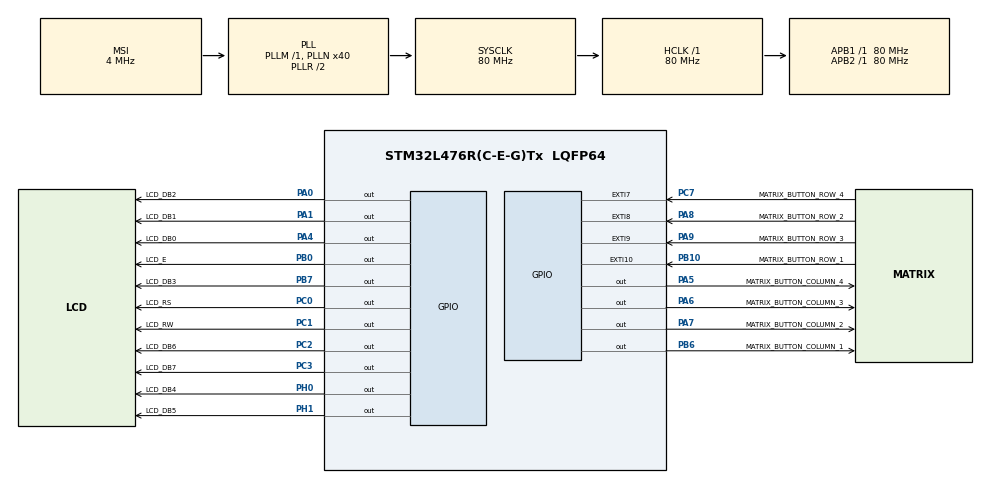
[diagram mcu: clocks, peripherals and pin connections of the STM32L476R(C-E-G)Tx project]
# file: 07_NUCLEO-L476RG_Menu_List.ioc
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Mcu.Family=STM32L4
Mcu.Name=STM32L476R(C-E-G)Tx
Mcu.Package=LQFP64
Mcu.UserConstants=TIMER_PRESCALER,7999;TIMER_COUNTER,9;LCD_TIMER_PRESCALER,1;LCD_TIMER_COUNTER,3
NVIC.EXTI15_10_IRQn=true\:1\:0\:true\:false\:true\:true\:true
NVIC.EXTI9_5_IRQn=true\:1\:0\:true\:false\:true\:true\:true
NVIC.PriorityGroup=NVIC_PRIORITYGROUP_4
NVIC.RTC_WKUP_IRQn=true\:0\:0\:false\:false\:true\:true\:true
NVIC.TIM6_DAC_IRQn=true\:1\:0\:true\:false\:true\:true\:true
NVIC.TIM7_IRQn=true\:0\:0\:true\:false\:true\:true\:true
PA0.GPIO_Label=LCD_DB2
PA0.GPIO_Speed=GPIO_SPEED_FREQ_VERY_HIGH
PA0.Signal=GPIO_Output
PA1.GPIO_Label=LCD_DB1
PA1.GPIO_Speed=GPIO_SPEED_FREQ_VERY_HIGH
PA1.Signal=GPIO_Output
PA4.GPIO_Label=LCD_DB0
PA4.GPIO_Speed=GPIO_SPEED_FREQ_VERY_HIGH
PA4.Signal=GPIO_Output
PA5.GPIO_Label=MATRIX_BUTTON_COLUMN_4
PA5.GPIO_ModeDefaultOutputPP=GPIO_MODE_OUTPUT_OD
PA5.Signal=GPIO_Output
PA6.GPIO_Label=MATRIX_BUTTON_COLUMN_3
PA6.GPIO_ModeDefaultOutputPP=GPIO_MODE_OUTPUT_OD
PA6.Signal=GPIO_Output
PA7.GPIO_Label=MATRIX_BUTTON_COLUMN_2
PA7.GPIO_ModeDefaultOutputPP=GPIO_MODE_OUTPUT_OD
PA7.Signal=GPIO_Output
PA8.GPIO_Label=MATRIX_BUTTON_ROW_2
PA8.GPIO_ModeDefaultEXTI=GPIO_MODE_IT_FALLING
PA8.GPIO_PuPd=GPIO_PULLUP
PA8.Signal=GPXTI8
PA9.GPIO_Label=MATRIX_BUTTON_ROW_3
PA9.GPIO_ModeDefaultEXTI=GPIO_MODE_IT_FALLING
PA9.GPIO_PuPd=GPIO_PULLUP
PA9.Signal=GPXTI9
PB0.GPIO_Label=LCD_E
PB0.GPIO_Speed=GPIO_SPEED_FREQ_VERY_HIGH
PB0.Signal=GPIO_Output
PB10.GPIO_Label=MATRIX_BUTTON_ROW_1
PB10.GPIO_ModeDefaultEXTI=GPIO_MODE_IT_FALLING
PB10.GPIO_PuPd=GPIO_PULLUP
PB10.Signal=GPXTI10
PB6.GPIO_Label=MATRIX_BUTTON_COLUMN_1
PB6.GPIO_ModeDefaultOutputPP=GPIO_MODE_OUTPUT_OD
PB6.Signal=GPIO_Output
PB7.GPIO_Label=LCD_DB3
PB7.GPIO_Speed=GPIO_SPEED_FREQ_VERY_HIGH
PB7.Signal=GPIO_Output
PC0.GPIO_Label=LCD_RS
PC0.GPIO_Speed=GPIO_SPEED_FREQ_VERY_HIGH
PC0.Signal=GPIO_Output
PC1.GPIO_Label=LCD_RW
PC1.GPIO_Speed=GPIO_SPEED_FREQ_VERY_HIGH
PC1.Signal=GPIO_Output
PC2.GPIO_Label=LCD_DB6
PC2.GPIO_Speed=GPIO_SPEED_FREQ_VERY_HIGH
PC2.Signal=GPIO_Output
PC3.GPIO_Label=LCD_DB7
PC3.GPIO_Speed=GPIO_SPEED_FREQ_VERY_HIGH
PC3.Signal=GPIO_Output
PC7.GPIO_Label=MATRIX_BUTTON_ROW_4
PC7.GPIO_ModeDefaultEXTI=GPIO_MODE_IT_FALLING
PC7.GPIO_PuPd=GPIO_PULLUP
PC7.Signal=GPXTI7
PH0-OSC_IN\ (PH0).GPIO_Label=LCD_DB4
PH0-OSC_IN\ (PH0).GPIO_Speed=GPIO_SPEED_FREQ_VERY_HIGH
PH0-OSC_IN\ (PH0).Signal=GPIO_Output
PH1-OSC_OUT\ (PH1).GPIO_Label=LCD_DB5
PH1-OSC_OUT\ (PH1).GPIO_Speed=GPIO_SPEED_FREQ_VERY_HIGH
PH1-OSC_OUT\ (PH1).Signal=GPIO_Output
ProjectManager.HeapSize=0x200
ProjectManager.StackSize=0x400
ProjectManager.TargetToolchain=STM32CubeIDE
RCC.AHBFreq_Value=80000000
RCC.APB1Freq_Value=80000000
RCC.APB1TimFreq_Value=80000000
RCC.APB2Freq_Value=80000000
RCC.APB2TimFreq_Value=80000000
RCC.CortexFreq_Value=80000000
RCC.HCLKFreq_Value=80000000
RCC.HSE_VALUE=8000000
RCC.HSI_VALUE=16000000
RCC.LSE_VALUE=32768
RCC.MSI_VALUE=4000000
RCC.PLLN=40
RCC.SYSCLKFreq_VALUE=80000000
RCC.SYSCLKSource=RCC_SYSCLKSOURCE_PLLCLK
RCC.VCOOutputFreq_Value=160000000
RTC.Date=26
RTC.Format=RTC_FORMAT_BIN
RTC.Hours=23
RTC.Minutes=30
RTC.Month=RTC_MONTH_MAY
RTC.Seconds=30
RTC.WakeUpClock-WakeUp=RTC_WAKEUPCLOCK_CK_SPRE_16BITS
RTC.WeekDay=RTC_WEEKDAY_TUESDAY
TIM6.Period=TIMER_COUNTER
TIM6.Prescaler=TIMER_PRESCALER
TIM7.Period=LCD_TIMER_COUNTER
TIM7.Prescaler=LCD_TIMER_PRESCALER
VP_RTC_VS_RTC_Activate.Mode=RTC_Enabled
VP_RTC_VS_RTC_Calendar.Mode=RTC_Calendar
VP_RTC_VS_RTC_WakeUp_intern.Mode=WakeUp
VP_TIM6_VS_ClockSourceINT.Mode=Enable_Timer
VP_TIM7_VS_ClockSourceINT.Mode=Enable_Timer
board=custom

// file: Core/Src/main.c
/* USER CODE BEGIN Header */
/**
  ******************************************************************************
  * @file           : main.c
  * @brief          : Main program body
  ******************************************************************************
  * @attention
  *
  * <h2><center>&copy; Copyright (c) 2020 STMicroelectronics.
  * All rights reserved.</center></h2>
  *
  * This software component is licensed by ST under BSD 3-Clause license,
  * the "License"; You may not use this file except in compliance with the
  * License. You may obtain a copy of the License at:
  *                        opensource.org/licenses/BSD-3-Clause
  *
  ******************************************************************************
  */
/* USER CODE END Header */

#include "main.h"
#include "rtc.h"
#include "tim.h"
#include "gpio.h"

/* USER CODE BEGIN Includes */
#include "common.h"
#include "main_loop.h"
/* USER CODE END Includes */

void SystemClock_Config(void);

int main(void)
{

  /* MCU Configuration--------------------------------------------------------*/

  /* Reset of all peripherals, Initializes the Flash interface and the Systick. */
  HAL_Init();

  /* Configure the system clock */
  SystemClock_Config();

  /* Initialize all configured peripherals */
  MX_GPIO_Init();
  MX_TIM6_Init();
  MX_TIM7_Init();
  MX_RTC_Init();

  /* Infinite loop */
  /* USER CODE BEGIN WHILE */
  while (1)
  {
	  MainLoop();
    /* USER CODE END WHILE */

  }
}

void SystemClock_Config(void)
{
  RCC_OscInitTypeDef RCC_OscInitStruct = {0};
  RCC_ClkInitTypeDef RCC_ClkInitStruct = {0};
  RCC_PeriphCLKInitTypeDef PeriphClkInit = {0};

  /** Initializes the CPU, AHB and APB busses clocks
  */
  RCC_OscInitStruct.OscillatorType = RCC_OSCILLATORTYPE_LSI|RCC_OSCILLATORTYPE_MSI;
  RCC_OscInitStruct.LSIState = RCC_LSI_ON;
  RCC_OscInitStruct.MSIState = RCC_MSI_ON;
  RCC_OscInitStruct.MSICalibrationValue = 0;
  RCC_OscInitStruct.MSIClockRange = RCC_MSIRANGE_6;
  RCC_OscInitStruct.PLL.PLLState = RCC_PLL_ON;
  RCC_OscInitStruct.PLL.PLLSource = RCC_PLLSOURCE_MSI;
  RCC_OscInitStruct.PLL.PLLM = 1;
  RCC_OscInitStruct.PLL.PLLN = 40;
  RCC_OscInitStruct.PLL.PLLP = RCC_PLLP_DIV7;
  RCC_OscInitStruct.PLL.PLLQ = RCC_PLLQ_DIV2;
  RCC_OscInitStruct.PLL.PLLR = RCC_PLLR_DIV2;
  if (HAL_RCC_OscConfig(&RCC_OscInitStruct) != HAL_OK)
  {
    Error_Handler();
  }
  /** Initializes the CPU, AHB and APB busses clocks
  */
  RCC_ClkInitStruct.ClockType = RCC_CLOCKTYPE_HCLK|RCC_CLOCKTYPE_SYSCLK
                              |RCC_CLOCKTYPE_PCLK1|RCC_CLOCKTYPE_PCLK2;
  RCC_ClkInitStruct.SYSCLKSource = RCC_SYSCLKSOURCE_PLLCLK;
  RCC_ClkInitStruct.AHBCLKDivider = RCC_SYSCLK_DIV1;
  RCC_ClkInitStruct.APB1CLKDivider = RCC_HCLK_DIV1;
  RCC_ClkInitStruct.APB2CLKDivider = RCC_HCLK_DIV1;

  if (HAL_RCC_ClockConfig(&RCC_ClkInitStruct, FLASH_LATENCY_4) != HAL_OK)
  {
    Error_Handler();
  }
  PeriphClkInit.PeriphClockSelection = RCC_PERIPHCLK_RTC;
  PeriphClkInit.RTCClockSelection = RCC_RTCCLKSOURCE_LSI;
  if (HAL_RCCEx_PeriphCLKConfig(&PeriphClkInit) != HAL_OK)
  {
    Error_Handler();
  }
  /** Configure the main internal regulator output voltage
  */
  if (HAL_PWREx_ControlVoltageScaling(PWR_REGULATOR_VOLTAGE_SCALE1) != HAL_OK)
  {
    Error_Handler();
  }
}

void Error_Handler(void)
{
}

/************************ (C) COPYRIGHT STMicroelectronics *****END OF FILE****/
